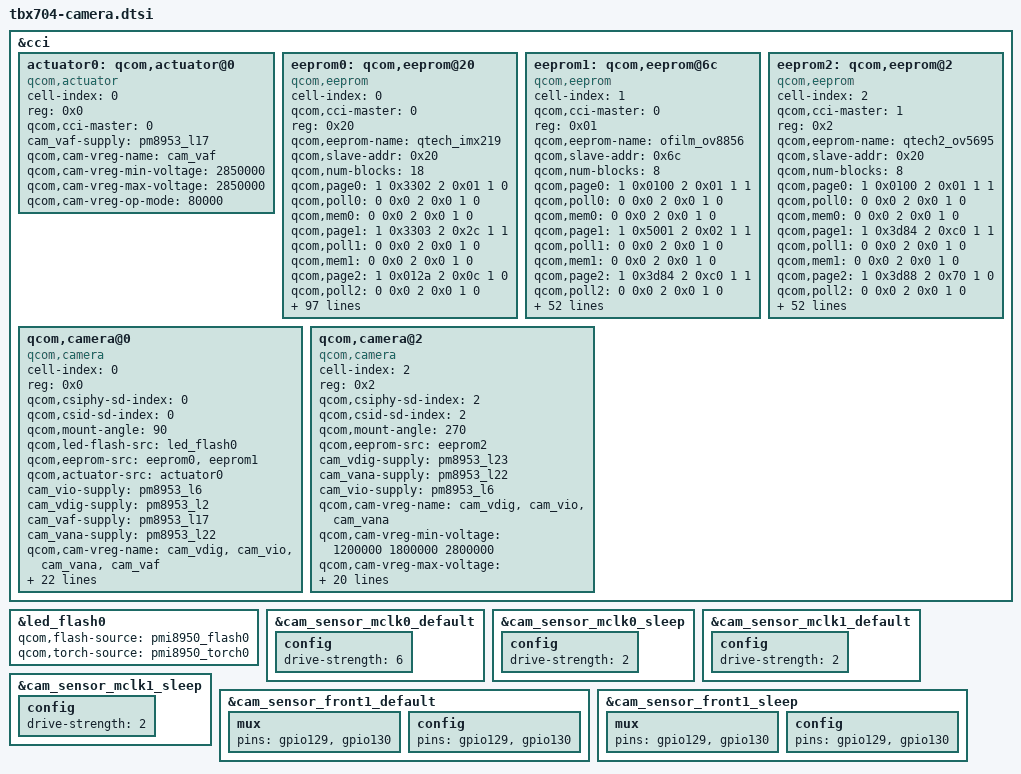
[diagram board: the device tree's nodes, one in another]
/*
 * Lenovo TAB4 10 Plus (TB-X704F/L) camera sensors
 *
 * Port of Lenovo's arch/arm/boot/dts/qcom/tbx704/
 * tbx704-msm8953-camera-sensor-qrd.dtsi (3.18), checked against the
 * stock "MSM8953 QRD SKU3" DTB (board-id 0x0b). The QRD reference nodes from
 * msm8953-camera-sensor-qrd.dtsi are dropped and rebuilt here, so this file
 * alone describes the camera hardware:
 *
 *  camera@0: rear, CCI0, actuator@0, EEPROMs qtech_imx219 / ofilm_ov8856
 *  camera@2: front OV5695, CCI1, EEPROM qtech2_ov5695
 *
 * The EEPROMs carry a name and memory map, so msm_eeprom probes and reads
 * them from the kernel; the camera daemon matches them by name
 * (CFG_EEPROM_GET_INFO). A module variant that is not fitted fails its
 * probe and is simply not registered.
 *
 * This program is free software; you can redistribute it and/or modify
 * it under the terms of the GNU General Public License version 2 and
 * only version 2 as published by the Free Software Foundation.
 */

&cci {
	/delete-node/ qcom,actuator@0;
	/delete-node/ qcom,eeprom@0;
	/delete-node/ qcom,eeprom@2;
	/delete-node/ qcom,camera@0;
	/delete-node/ qcom,camera@1;
	/delete-node/ qcom,camera@2;
};

&cci {
	#address-cells = <1>;
	#size-cells = <0>;

	actuator0: qcom,actuator@0 {
		cell-index = <0>;
		reg = <0x0>;
		compatible = "qcom,actuator";
		qcom,cci-master = <0>;
		cam_vaf-supply = <&pm8953_l17>;
		qcom,cam-vreg-name = "cam_vaf";
		qcom,cam-vreg-min-voltage = <2850000>;
		qcom,cam-vreg-max-voltage = <2850000>;
		qcom,cam-vreg-op-mode = <80000>;
	};

	/* rear module variant: Qtech IMX219 OTP */
	eeprom0: qcom,eeprom@20 {
		cell-index = <0>;
		compatible = "qcom,eeprom";
		qcom,cci-master = <0>;
		reg = <0x20>;
		qcom,eeprom-name = "qtech_imx219";
		qcom,slave-addr = <0x20>;

		/* blocks 18..22 are present in Lenovo's tree but unused */
		qcom,num-blocks = <18>;
		qcom,page0 = <1 0x3302 2 0x01 1 0>;
		qcom,poll0 = <0 0x0 2 0x0 1 0>;
		qcom,mem0 = <0 0x0 2 0x0 1 0>;
		qcom,page1 = <1 0x3303 2 0x2c 1 1>;
		qcom,poll1 = <0 0x0 2 0x0 1 0>;
		qcom,mem1 = <0 0x0 2 0x0 1 0>;
		qcom,page2 = <1 0x012a 2 0x0c 1 0>;
		qcom,poll2 = <0 0x0 2 0x0 1 0>;
		qcom,mem2 = <0 0x0 2 0x0 1 0>;
		qcom,page3 = <1 0x012b 2 0x00 1 0>;
		qcom,poll3 = <0 0x0 2 0x0 1 0>;
		qcom,mem3 = <0 0x0 2 0x0 1 0>;
		qcom,page4 = <1 0x3300 2 0x08 1 0>;
		qcom,poll4 = <0 0x0 2 0x0 1 0>;
		qcom,mem4 = <0 0x0 2 0x0 1 0>;
		qcom,page5 = <1 0x3200 2 0x01 1 5>;
		qcom,poll5 = <0 0x0 2 0x0 1 0>;
		qcom,mem5 = <0 0x0 2 0x0 1 0>;
		qcom,page6 = <1 0x3202 2 0x00 1 0>;
		qcom,poll6 = <0 0x0 2 0x0 1 0>;
		qcom,mem6 = <64 0x3204 2 0x0 1 0>;
		qcom,page7 = <1 0x3202 2 0x01 1 0>;
		qcom,poll7 = <0 0x0 2 0x0 1 0>;
		qcom,mem7 = <64 0x3204 2 0x0 1 0>;
		qcom,page8 = <1 0x3300 2 0x00 1 0>;
		qcom,poll8 = <0 0x0 2 0x0 1 0>;
		qcom,mem8 = <0 0x3204 2 0x0 1 0>;
		qcom,page9 = <1 0x3202 2 0x02 1 0>;
		qcom,poll9 = <0 0x0 2 0x0 1 0>;
		qcom,mem9 = <64 0x3204 2 0x0 1 0>;
		qcom,page10 = <1 0x3202 2 0x03 1 0>;
		qcom,poll10 = <0 0x0 2 0x0 1 0>;
		qcom,mem10 = <64 0x3204 2 0x0 1 0>;
		qcom,page11 = <1 0x3202 2 0x04 1 0>;
		qcom,poll11 = <0 0x0 2 0x0 1 0>;
		qcom,mem11 = <64 0x3204 2 0x0 1 0>;
		qcom,page12 = <1 0x3202 2 0x05 1 0>;
		qcom,poll12 = <0 0x0 2 0x0 1 0>;
		qcom,mem12 = <64 0x3204 2 0x0 1 0>;
		qcom,page13 = <1 0x3202 2 0x06 1 0>;
		qcom,poll13 = <0 0x0 2 0x0 1 0>;
		qcom,mem13 = <64 0x3204 2 0x0 1 0>;
		qcom,page14 = <1 0x3202 2 0x07 1 0>;
		qcom,poll14 = <0 0x0 2 0x0 1 0>;
		qcom,mem14 = <64 0x3204 2 0x0 1 0>;
		qcom,page15 = <1 0x3202 2 0x08 1 0>;
		qcom,poll15 = <0 0x0 2 0x0 1 0>;
		qcom,mem15 = <64 0x3204 2 0x0 1 0>;
		qcom,page16 = <1 0x3202 2 0x09 1 0>;
		qcom,poll16 = <0 0x0 2 0x0 1 0>;
		qcom,mem16 = <64 0x3204 2 0x0 1 0>;
		qcom,page17 = <1 0x3202 2 0x0a 1 0>;
		qcom,poll17 = <0 0x0 2 0x0 1 0>;
		qcom,mem17 = <64 0x3204 2 0x0 1 0>;
		qcom,page18 = <1 0x0190 2 0x01 1 0>;
		qcom,poll18 = <0 0x0 2 0x0 1 0>;
		qcom,mem18 = <0 0x3204 2 0x0 1 0>;
		qcom,page19 = <1 0x0192 2 0x00 1 0>;
		qcom,poll19 = <0 0x0 2 0x0 1 0>;
		qcom,mem19 = <0 0x3204 2 0x0 1 0>;
		qcom,page20 = <1 0x0191 2 0x00 1 0>;
		qcom,poll20 = <0 0x0 2 0x0 1 0>;
		qcom,mem20 = <0 0x3204 2 0x0 1 0>;
		qcom,page21 = <1 0x0193 2 0x00 1 0>;
		qcom,poll21 = <0 0x0 2 0x0 1 0>;
		qcom,mem21 = <0 0x3204 2 0x0 1 0>;
		qcom,page22 = <1 0x01a4 2 0x03 1 0>;
		qcom,poll22 = <0 0x0 2 0x0 1 0>;
		qcom,mem22 = <0 0x3204 2 0x0 1 0>;

		cam_vio-supply = <&pm8953_l6>;
		cam_vdig-supply = <&pm8953_l2>;
		cam_vana-supply = <&pm8953_l22>;
		cam_vaf-supply = <&pm8953_l17>;
		qcom,cam-vreg-name = "cam_vio", "cam_vdig", "cam_vana",
				     "cam_vaf";
		qcom,cam-vreg-min-voltage = <0 1100000 2800000 2850000>;
		qcom,cam-vreg-max-voltage = <0 1100000 2800000 2850000>;
		qcom,cam-vreg-op-mode = <0 105000 80000 100000>;
		pinctrl-names = "cam_default", "cam_suspend";
		pinctrl-0 = <&cam_sensor_mclk0_default
				&cam_sensor_rear_default>;
		pinctrl-1 = <&cam_sensor_mclk0_sleep
				&cam_sensor_rear_sleep>;
		gpios = <&tlmm 26 0>,
			<&tlmm 40 0>,
			<&tlmm 39 0>;
		qcom,gpio-reset = <1>;
		qcom,gpio-standby = <2>;
		qcom,gpio-req-tbl-num = <0 1 2>;
		qcom,gpio-req-tbl-flags = <1 0 0>;
		qcom,gpio-req-tbl-label = "CAMIF_MCLK0",
					  "CAM_RESET0",
					  "CAM_STANDBY0";
		qcom,cam-power-seq-type = "sensor_vreg", "sensor_vreg",
					  "sensor_vreg", "sensor_clk",
					  "sensor_gpio", "sensor_gpio",
					  "sensor_gpio", "sensor_gpio";
		qcom,cam-power-seq-val = "cam_vdig", "cam_vana", "cam_vio",
					 "sensor_cam_mclk",
					 "sensor_gpio_reset",
					 "sensor_gpio_reset",
					 "sensor_gpio_standby",
					 "sensor_gpio_standby";
		qcom,cam-power-seq-cfg-val = <0 0 0 24000000 0 1 0 1>;
		qcom,cam-power-seq-delay = <0 0 0 1 1 1 1 10>;
		status = "ok";
		clocks = <&clock_gcc clk_mclk0_clk_src>,
			 <&clock_gcc clk_gcc_camss_mclk0_clk>;
		clock-names = "cam_src_clk", "cam_clk";
		qcom,clock-rates = <19200000 0>;
	};

	/* rear module variant: O-Film OV8856 OTP */
	eeprom1: qcom,eeprom@6c {
		cell-index = <1>;
		compatible = "qcom,eeprom";
		qcom,cci-master = <0>;
		reg = <0x01>;
		qcom,eeprom-name = "ofilm_ov8856";
		qcom,slave-addr = <0x6c>;

		qcom,num-blocks = <8>;
		qcom,page0 = <1 0x0100 2 0x01 1 1>;
		qcom,poll0 = <0 0x0 2 0x0 1 0>;
		qcom,mem0 = <0 0x0 2 0x0 1 0>;
		qcom,page1 = <1 0x5001 2 0x02 1 1>;
		qcom,poll1 = <0 0x0 2 0x0 1 0>;
		qcom,mem1 = <0 0x0 2 0x0 1 0>;
		qcom,page2 = <1 0x3d84 2 0xc0 1 1>;
		qcom,poll2 = <0 0x0 2 0x0 1 0>;
		qcom,mem2 = <0 0x0 2 0x0 1 0>;
		qcom,page3 = <1 0x3d88 2 0x70 1 0>;
		qcom,poll3 = <0 0x0 2 0x0 1 0>;
		qcom,mem3 = <0 0x0 2 0x0 1 0>;
		qcom,page4 = <1 0x3d89 2 0x10 1 0>;
		qcom,poll4 = <0 0x0 2 0x0 1 0>;
		qcom,mem4 = <0 0x0 2 0x0 1 0>;
		qcom,page5 = <1 0x3d8a 2 0x72 1 0>;
		qcom,poll5 = <0 0x0 2 0x0 1 0>;
		qcom,mem5 = <0 0x0 2 0x0 1 0>;
		qcom,page6 = <1 0x3d8b 2 0x0d 1 0>;
		qcom,poll6 = <0 0x0 2 0x0 1 0>;
		qcom,mem6 = <0 0x0 2 0x0 1 0>;
		qcom,page7 = <1 0x3d81 2 0x01 1 10>;
		qcom,poll7 = <0 0x0 2 0x0 1 0>;
		qcom,mem7 = <510 0x7010 2 0x0 1 0>;

		cam_vio-supply = <&pm8953_l6>;
		cam_vdig-supply = <&pm8953_l2>;
		cam_vana-supply = <&pm8953_l22>;
		cam_vaf-supply = <&pm8953_l17>;
		qcom,cam-vreg-name = "cam_vio", "cam_vdig", "cam_vana",
				     "cam_vaf";
		qcom,cam-vreg-min-voltage = <0 1100000 2800000 2850000>;
		qcom,cam-vreg-max-voltage = <0 1100000 2800000 2850000>;
		qcom,cam-vreg-op-mode = <0 105000 80000 100000>;
		pinctrl-names = "cam_default", "cam_suspend";
		pinctrl-0 = <&cam_sensor_mclk0_default
				&cam_sensor_rear_default>;
		pinctrl-1 = <&cam_sensor_mclk0_sleep
				&cam_sensor_rear_sleep>;
		gpios = <&tlmm 26 0>,
			<&tlmm 40 0>,
			<&tlmm 39 0>;
		qcom,gpio-reset = <1>;
		qcom,gpio-standby = <2>;
		qcom,gpio-req-tbl-num = <0 1 2>;
		qcom,gpio-req-tbl-flags = <1 0 0>;
		qcom,gpio-req-tbl-label = "CAMIF_MCLK0",
					  "CAM_RESET0",
					  "CAM_STANDBY0";
		qcom,cam-power-seq-type = "sensor_vreg", "sensor_vreg",
					  "sensor_vreg", "sensor_clk",
					  "sensor_gpio", "sensor_gpio",
					  "sensor_gpio", "sensor_gpio";
		qcom,cam-power-seq-val = "cam_vdig", "cam_vana", "cam_vio",
					 "sensor_cam_mclk",
					 "sensor_gpio_reset",
					 "sensor_gpio_reset",
					 "sensor_gpio_standby",
					 "sensor_gpio_standby";
		qcom,cam-power-seq-cfg-val = <0 0 0 24000000 0 1 0 1>;
		qcom,cam-power-seq-delay = <0 0 0 1 1 1 1 10>;
		status = "ok";
		clocks = <&clock_gcc clk_mclk0_clk_src>,
			 <&clock_gcc clk_gcc_camss_mclk0_clk>;
		clock-names = "cam_src_clk", "cam_clk";
		qcom,clock-rates = <19200000 0>;
	};

	/* front module variant: Qtech OV5695 OTP */
	eeprom2: qcom,eeprom@2 {
		cell-index = <2>;
		compatible = "qcom,eeprom";
		qcom,cci-master = <1>;
		reg = <0x2>;
		qcom,eeprom-name = "qtech2_ov5695";
		qcom,slave-addr = <0x20>;

		qcom,num-blocks = <8>;
		qcom,page0 = <1 0x0100 2 0x01 1 1>;
		qcom,poll0 = <0 0x0 2 0x0 1 0>;
		qcom,mem0 = <0 0x0 2 0x0 1 0>;
		qcom,page1 = <1 0x3d84 2 0xc0 1 1>;
		qcom,poll1 = <0 0x0 2 0x0 1 0>;
		qcom,mem1 = <0 0x0 2 0x0 1 0>;
		qcom,page2 = <1 0x3d88 2 0x70 1 0>;
		qcom,poll2 = <0 0x0 2 0x0 1 0>;
		qcom,mem2 = <0 0x0 2 0x0 1 0>;
		qcom,page3 = <1 0x3d89 2 0x0c 1 0>;
		qcom,poll3 = <0 0x0 2 0x0 1 0>;
		qcom,mem3 = <0 0x0 2 0x0 1 0>;
		qcom,page4 = <1 0x3d8a 2 0x70 1 0>;
		qcom,poll4 = <0 0x0 2 0x0 1 0>;
		qcom,mem4 = <0 0x0 2 0x0 1 0>;
		qcom,page5 = <1 0x3d8b 2 0x1a 1 0>;
		qcom,poll5 = <0 0x0 2 0x0 1 0>;
		qcom,mem5 = <0 0x0 2 0x0 1 0>;
		qcom,page6 = <16 0x700c 2 0x00 1 0>;
		qcom,poll6 = <0 0x0 2 0x0 1 0>;
		qcom,mem6 = <0 0x0 2 0x0 1 0>;
		qcom,page7 = <1 0x3d81 2 0x01 1 10>;
		qcom,poll7 = <0 0x0 2 0x0 1 0>;
		qcom,mem7 = <16 0x700c 2 0x0 1 0>;

		cam_vdig-supply = <&pm8953_l23>;
		cam_vana-supply = <&pm8953_l22>;
		cam_vio-supply = <&pm8953_l6>;
		qcom,cam-vreg-name = "cam_vdig", "cam_vio", "cam_vana";
		qcom,cam-vreg-min-voltage = <1200000 1800000 2800000>;
		qcom,cam-vreg-max-voltage = <1200000 1800000 2800000>;
		qcom,cam-vreg-op-mode = <105000 80000 80000>;
		qcom,gpio-no-mux = <0>;
		pinctrl-names = "cam_default", "cam_suspend";
		pinctrl-0 = <&cam_sensor_mclk1_default
				&cam_sensor_front1_default>;
		pinctrl-1 = <&cam_sensor_mclk1_sleep
				&cam_sensor_front1_sleep>;
		gpios = <&tlmm 27 0>,
			<&tlmm 129 0>,
			<&tlmm 130 0>;
		qcom,gpio-reset = <1>;
		qcom,gpio-standby = <2>;
		qcom,gpio-req-tbl-num = <0 1 2>;
		qcom,gpio-req-tbl-flags = <1 0 0>;
		qcom,gpio-req-tbl-label = "CAMIF_MCLK2",
					  "CAM_RESET2",
					  "CAM_STANDBY2";
		qcom,cam-power-seq-type = "sensor_gpio", "sensor_gpio",
					  "sensor_vreg", "sensor_vreg",
					  "sensor_vreg", "sensor_clk",
					  "sensor_gpio", "sensor_gpio";
		qcom,cam-power-seq-val = "sensor_gpio_reset",
					 "sensor_gpio_standby",
					 "cam_vana", "cam_vdig", "cam_vio",
					 "sensor_cam_mclk",
					 "sensor_gpio_reset",
					 "sensor_gpio_standby";
		qcom,cam-power-seq-cfg-val = <0 0 1 1 1 24000000 1 1>;
		qcom,cam-power-seq-delay = <1 1 0 0 0 1 1 1>;
		status = "ok";
		clocks = <&clock_gcc clk_mclk1_clk_src>,
			 <&clock_gcc clk_gcc_camss_mclk1_clk>;
		clock-names = "cam_src_clk", "cam_clk";
		qcom,clock-rates = <19200000 0>;
	};

	/* rear */
	qcom,camera@0 {
		cell-index = <0>;
		compatible = "qcom,camera";
		reg = <0x0>;
		qcom,csiphy-sd-index = <0>;
		qcom,csid-sd-index = <0>;
		qcom,mount-angle = <90>;
		qcom,led-flash-src = <&led_flash0>;
		qcom,eeprom-src = <&eeprom0 &eeprom1>;
		qcom,actuator-src = <&actuator0>;
		cam_vio-supply = <&pm8953_l6>;
		cam_vdig-supply = <&pm8953_l2>;
		cam_vaf-supply = <&pm8953_l17>;
		cam_vana-supply = <&pm8953_l22>;
		qcom,cam-vreg-name = "cam_vdig", "cam_vio", "cam_vana",
				     "cam_vaf";
		qcom,cam-vreg-min-voltage = <1200000 0 2800000 2850000>;
		qcom,cam-vreg-max-voltage = <1200000 0 2800000 2850000>;
		qcom,cam-vreg-op-mode = <200000 0 80000 100000>;
		pinctrl-names = "cam_default", "cam_suspend";
		pinctrl-0 = <&cam_sensor_mclk0_default
				&cam_sensor_rear_default>;
		pinctrl-1 = <&cam_sensor_mclk0_sleep
				&cam_sensor_rear_sleep>;
		gpios = <&tlmm 26 0>,
			<&tlmm 40 0>,
			<&tlmm 39 0>;
		qcom,gpio-reset = <1>;
		qcom,gpio-standby = <2>;
		qcom,gpio-req-tbl-num = <0 1 2>;
		qcom,gpio-req-tbl-flags = <1 0 0>;
		qcom,gpio-req-tbl-label = "CAMIF_MCLK0",
					  "CAM_RESET0",
					  "CAM_STANDBY0";
		qcom,sensor-position = <0>;
		qcom,sensor-mode = <0>;
		qcom,cci-master = <0>;
		status = "ok";
		clocks = <&clock_gcc clk_mclk0_clk_src>,
			 <&clock_gcc clk_gcc_camss_mclk0_clk>;
		clock-names = "cam_src_clk", "cam_clk";
		qcom,clock-rates = <24000000 0>;
	};

	/* front: OV5695 */
	qcom,camera@2 {
		cell-index = <2>;
		compatible = "qcom,camera";
		reg = <0x2>;
		qcom,csiphy-sd-index = <2>;
		qcom,csid-sd-index = <2>;
		qcom,mount-angle = <270>;
		qcom,eeprom-src = <&eeprom2>;
		cam_vdig-supply = <&pm8953_l23>;
		cam_vana-supply = <&pm8953_l22>;
		cam_vio-supply = <&pm8953_l6>;
		qcom,cam-vreg-name = "cam_vdig", "cam_vio", "cam_vana";
		qcom,cam-vreg-min-voltage = <1200000 1800000 2800000>;
		qcom,cam-vreg-max-voltage = <1200000 1800000 2800000>;
		qcom,cam-vreg-op-mode = <105000 80000 80000>;
		qcom,gpio-no-mux = <0>;
		pinctrl-names = "cam_default", "cam_suspend";
		pinctrl-0 = <&cam_sensor_mclk1_default
				&cam_sensor_front1_default>;
		pinctrl-1 = <&cam_sensor_mclk1_sleep
				&cam_sensor_front1_sleep>;
		gpios = <&tlmm 27 0>,
			<&tlmm 129 0>,
			<&tlmm 130 0>;
		qcom,gpio-reset = <1>;
		qcom,gpio-standby = <2>;
		qcom,gpio-req-tbl-num = <0 1 2>;
		qcom,gpio-req-tbl-flags = <1 0 0>;
		qcom,gpio-req-tbl-label = "CAMIF_MCLK2",
					  "CAM_RESET2",
					  "CAM_STANDBY2";
		qcom,sensor-position = <1>;
		qcom,sensor-mode = <1>;
		qcom,cci-master = <1>;
		status = "ok";
		clocks = <&clock_gcc clk_mclk1_clk_src>,
			 <&clock_gcc clk_gcc_camss_mclk1_clk>;
		clock-names = "cam_src_clk", "cam_clk";
		qcom,clock-rates = <24000000 0>;
	};
};

/* single flash/torch LED as in Lenovo's tree */
&led_flash0 {
	qcom,flash-source = <&pmi8950_flash0>;
	qcom,torch-source = <&pmi8950_torch0>;
};

/* camera pin states as in Lenovo's tree */
&cam_sensor_mclk0_default {
	config {
		drive-strength = <6>;
	};
};

&cam_sensor_mclk0_sleep {
	config {
		drive-strength = <2>;
	};
};

&cam_sensor_mclk1_default {
	config {
		drive-strength = <2>;
	};
};

&cam_sensor_mclk1_sleep {
	config {
		drive-strength = <2>;
	};
};

/* front OV5695: reset on gpio129, standby on gpio130 */
&cam_sensor_front1_default {
	mux {
		pins = "gpio129", "gpio130";
	};

	config {
		pins = "gpio129", "gpio130";
	};
};

&cam_sensor_front1_sleep {
	mux {
		pins = "gpio129", "gpio130";
	};

	config {
		pins = "gpio129", "gpio130";
	};
};
